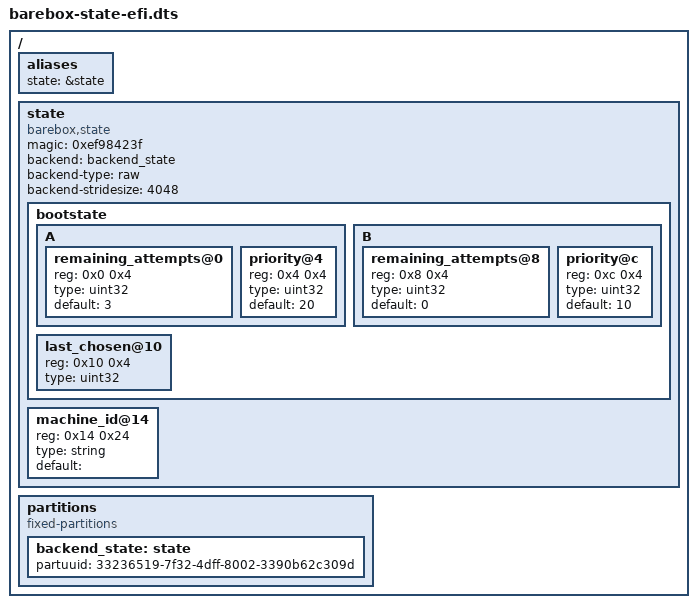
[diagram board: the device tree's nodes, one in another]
/dts-v1/;
/ {

	aliases {
		state = &state;
	};

	state: state {
		#address-cells = <1>;
		#size-cells = <1>;
		
		magic = <0xef98423f>;
		compatible = "barebox,state";
		backend = <&backend_state>;
		backend-type = "raw";
		backend-stridesize = <4048>;

		bootstate {
			#address-cells = <1>;
			#size-cells = <1>;

			A {
				#address-cells = <1>;
				#size-cells = <1>;
				remaining_attempts@0 {
					reg = <0x0 0x4>;
					type = "uint32";
					default = <3>;
				};
				priority@4 {
					reg = <0x4 0x4>;
					type = "uint32";
					default = <20>;
				};
			};

			B {
				#address-cells = <1>;
				#size-cells = <1>;
				remaining_attempts@8 {
					reg = <0x8 0x4>;
					type = "uint32";
					default = <0>;
				};
				priority@c {
					reg = <0xc 0x4>;
					type = "uint32";
					default = <10>;
				};
			};

			last_chosen@10 {
				reg = <0x10 0x4>;
				type = "uint32";
			};
		};

		machine_id@14 {
			reg = <0x14 0x24>;
			type = "string";
			default = "";
		};
	};

	partitions {
		#address-cells = <1>;
		#size-cells = <1>;
		compatible = "fixed-partitions";

		backend_state: state {
			partuuid = "33236519-7f32-4dff-8002-3390b62c309d";
		};
	};

};

